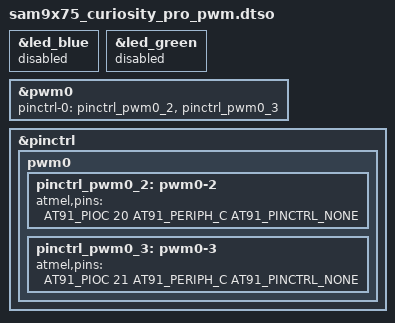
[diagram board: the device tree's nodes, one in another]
// SPDX-License-Identifier: (GPL-2.0+ OR MIT)
/*
 * Device Tree file for SAM9X75 Curiosity Pro board overlay blob for PWM signals.
 *
 * Copyright (C) 2026 Microchip Technology, Inc.
 * Author: Ryan Wanner <ryan.wanner@microchip.com>
 *
 */

/dts-v1/;
/plugin/;
#include "dt-bindings/pinctrl/at91.h"

&led_blue {
	status = "disabled"; /* Conflict between PWM0_2 and Blue LED */
};

&led_green {
	status = "disabled"; /* Conflict between PWM0_3 and Green LED */
};

&pwm0 {
        pinctrl-names = "default";
        pinctrl-0 = <&pinctrl_pwm0_2 &pinctrl_pwm0_3>;
        status = "okay";
};

&pinctrl {
	pwm0 {
		pinctrl_pwm0_2: pwm0-2 {
			atmel,pins = <AT91_PIOC 20 AT91_PERIPH_C AT91_PINCTRL_NONE>;
		};

		pinctrl_pwm0_3: pwm0-3 {
			atmel,pins = <AT91_PIOC 21 AT91_PERIPH_C AT91_PINCTRL_NONE>;
		};
	};
};
